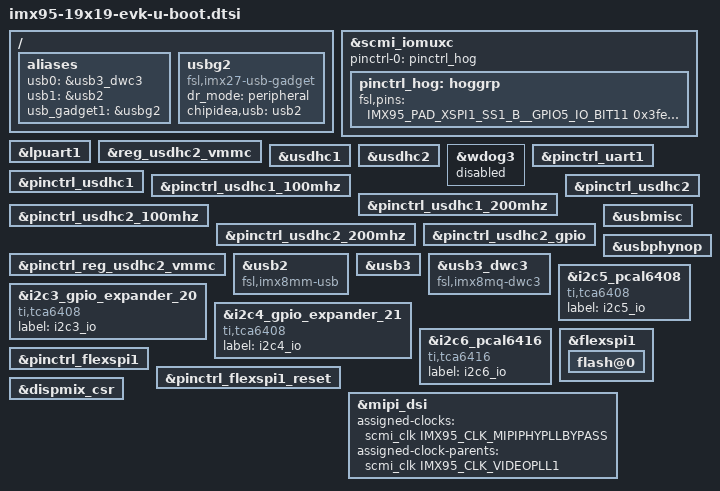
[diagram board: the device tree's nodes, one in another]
// SPDX-License-Identifier: GPL-2.0+
/*
 * Copyright 2025 NXP
 */

#include "imx95-u-boot.dtsi"
#include "imx95-19x19-evk-local.dtsi"

/ {
	aliases {
		usb0 = &usb3_dwc3;
		usb1 = &usb2;
		usb_gadget1 = &usbg2;
	};

	usbg2: usbg2 {
		compatible = "fsl,imx27-usb-gadget";
		dr_mode = "peripheral";
		chipidea,usb = <&usb2>;
		bootph-pre-ram;
		status = "okay";
	};
};

&scmi_iomuxc {
	pinctrl-names = "default";
	pinctrl-0 = <&pinctrl_hog>;

	pinctrl_hog: hoggrp {
		bootph-pre-ram;

		fsl,pins = <
			IMX95_PAD_XSPI1_SS1_B__GPIO5_IO_BIT11			0x3fe
			IMX95_PAD_GPIO_IO12__TPM3_CH2           0x51e
			IMX95_PAD_CCM_CLKO1__GPIO3_IO_BIT26			0x3fe
			IMX95_PAD_CCM_CLKO2__GPIO3_IO_BIT27			0x3fe
		>;
	};
};

&lpuart1 {
	bootph-pre-ram;
};

&reg_usdhc2_vmmc {
	bootph-pre-ram;
};

&usdhc1 {
	bootph-pre-ram;
};

&usdhc2 {
	bootph-pre-ram;
};

&wdog3 {
	status = "disabled";
};

&pinctrl_uart1 {
	bootph-pre-ram;
};

&pinctrl_usdhc1 {
	bootph-pre-ram;
};

&pinctrl_usdhc1_100mhz {
	bootph-pre-ram;
};

&pinctrl_usdhc1_200mhz {
	bootph-pre-ram;
};

&pinctrl_usdhc2 {
	bootph-pre-ram;
};

&pinctrl_usdhc2_100mhz {
	bootph-pre-ram;
};

&pinctrl_usdhc2_200mhz {
	bootph-pre-ram;
};

&pinctrl_usdhc2_gpio {
	bootph-pre-ram;
};

&pinctrl_reg_usdhc2_vmmc {
	bootph-pre-ram;
};

&usb2 {
	compatible = "fsl,imx8mm-usb", "fsl,imx7d-usb";
	/delete-property/power-domains;
	bootph-pre-ram;
};

&usbmisc {
	bootph-pre-ram;
};

&usbphynop {
	bootph-pre-ram;
};

&usb3 {
	/delete-property/power-domains;
};

&usb3_dwc3 {
	compatible = "fsl,imx8mq-dwc3", "snps,dwc3";
};

&i2c3_gpio_expander_20 {
	compatible = "ti,tca6408";
	label = "i2c3_io";
};

&i2c4_gpio_expander_21 {
	compatible = "ti,tca6408";
	label = "i2c4_io";
};

&i2c5_pcal6408 {
	compatible = "ti,tca6408";
	label = "i2c5_io";
};

&i2c6_pcal6416 {
	compatible = "ti,tca6416";
	label = "i2c6_io";
};

&flexspi1 {
	bootph-pre-ram;

	flash@0{
		bootph-pre-ram;
	};
};

&pinctrl_flexspi1 {
	bootph-pre-ram;
};

&pinctrl_flexspi1_reset {
	bootph-pre-ram;
};

&dispmix_csr {
	/delete-property/ assigned-clocks;
	/delete-property/ assigned-clock-rates;
	/delete-property/ assigned-clock-parents;
};

&mipi_dsi {
	assigned-clocks = <&scmi_clk IMX95_CLK_MIPIPHYPLLBYPASS>;
	assigned-clock-parents = <&scmi_clk IMX95_CLK_VIDEOPLL1>;
};
